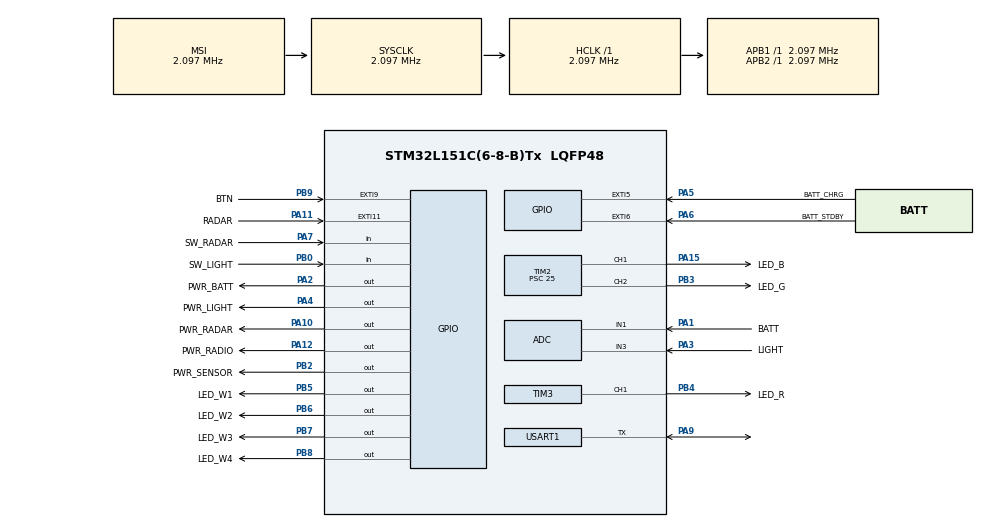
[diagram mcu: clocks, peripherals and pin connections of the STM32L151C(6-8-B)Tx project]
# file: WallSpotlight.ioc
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Mcu.Family=STM32L1
Dma.ADC.0.Mode=DMA_CIRCULAR
USART1.BaudRate=57600
NVIC.RTC_WKUP_IRQn=true\:0\:0\:false\:false\:true\:true\:true
ADC.SamplingTime-19\#ChannelRegularConversion=ADC_SAMPLETIME_96CYCLES
Dma.ADC.0.Priority=DMA_PRIORITY_LOW
VP_RTC_VS_RTC_Activate.Mode=RTC_Enabled
ADC.ScanConvMode=ADC_SCAN_ENABLE
PB6.GPIO_Label=LED_W2
PA6.GPIO_Label=BATT_STDBY
PB0.GPIO_Label=SW_LIGHT
PA11.GPIO_PuPd=GPIO_PULLDOWN
TIM2.Channel-PWM\ Generation2\ CH2=TIM_CHANNEL_2
ProjectManager.StackSize=0x400
ADC.Channel-19\#ChannelRegularConversion=ADC_CHANNEL_VREFINT
RTC.WakeUpClock-WakeUp=RTC_WAKEUPCLOCK_CK_SPRE_16BITS
ADC.NbrOfConversion=3
PA15.GPIO_Label=LED_B
PA12.Signal=GPIO_Output
PA10.PinState=GPIO_PIN_SET
Dma.ADC.0.PeriphInc=DMA_PINC_DISABLE
RCC.HCLKFreq_Value=2097000
RCC.APB2TimFreq_Value=2097000
TIM3.Period=255
PB6.Signal=GPIO_Output
PB9.GPIO_ModeDefaultEXTI=GPIO_MODE_IT_FALLING
RCC.AHBFreq_Value=2097000
Dma.ADC.0.Direction=DMA_PERIPH_TO_MEMORY
TIM3.Channel-PWM\ Generation1\ CH1=TIM_CHANNEL_1
ADC.Channel-17\#ChannelRegularConversion=ADC_CHANNEL_1
NVIC.EXTI15_10_IRQn=true\:0\:0\:false\:false\:true\:true\:true
PA12.PinState=GPIO_PIN_SET
RCC.HSE_VALUE=24000000
PB2.Signal=GPIO_Output
RCC.RTCClockSelection=RCC_RTCCLKSOURCE_LSE
PA2.PinState=GPIO_PIN_SET
PA6.GPIO_PuPd=GPIO_PULLUP
PC14-OSC32_IN.Mode=LSE-External-Oscillator
RCC.RTCClockSelectionVirtual=RCC_RTCCLKSOURCE_LSE
PA14.Mode=Serial_Wire
TIM3.Prescaler=25
PA5.GPIO_PuPd=GPIO_PULLUP
PA10.GPIO_Label=PWR_RADAR
PB7.Signal=GPIO_Output
TIM2.Channel-PWM\ Generation1\ CH1=TIM_CHANNEL_1
SH.S_TIM3_CH1.0=TIM3_CH1,PWM Generation1 CH1
Dma.ADC.0.MemInc=DMA_MINC_ENABLE
PB7.GPIO_Label=LED_W3
Mcu.Package=LQFP48
PB9.Signal=GPXTI9
TIM2.Prescaler=25
PA6.Signal=GPXTI6
PA2.GPIO_ModeDefaultOutputPP=GPIO_MODE_OUTPUT_OD
PA2.GPIO_Label=PWR_BATT
Dma.ADC.0.Instance=DMA1_Channel1
RTC.WakeUpCounter-WakeUp=1111
PA10.Signal=GPIO_Output
PB9.GPIO_PuPd=GPIO_PULLUP
VP_RTC_VS_RTC_Calendar.Mode=RTC_Calendar
ADC.Rank-19\#ChannelRegularConversion=3
PA15.Signal=S_TIM2_CH1_ETR
Dma.ADC.0.MemDataAlignment=DMA_MDATAALIGN_WORD
PB5.GPIO_Label=LED_W1
RCC.APB1TimFreq_Value=2097000
ADC.SamplingTime-18\#ChannelRegularConversion=ADC_SAMPLETIME_96CYCLES
Dma.Request0=ADC
PA4.GPIO_Label=PWR_LIGHT
PB4.Signal=S_TIM3_CH1
PA3.Signal=ADC_IN3
PB3.GPIO_Label=LED_G
ADC.Rank-17\#ChannelRegularConversion=1
RCC.MSI_VALUE=2097000
PC15-OSC32_OUT.Mode=LSE-External-Oscillator
ADC.Channel-18\#ChannelRegularConversion=ADC_CHANNEL_3
PA5.GPIO_ModeDefaultEXTI=GPIO_MODE_IT_RISING_FALLING
PA6.GPIO_ModeDefaultEXTI=GPIO_MODE_IT_RISING_FALLING
PB9.GPIO_Label=BTN
VP_ADC_Vref_Input.Mode=IN-Vrefint
PA11.GPIO_Label=RADAR
PC14-OSC32_IN.Signal=RCC_OSC32_IN
PA12.GPIO_Label=PWR_RADIO
Dma.ADC.0.PeriphDataAlignment=DMA_PDATAALIGN_WORD
PA3.Mode=IN3
PA13.Signal=SYS_JTMS-SWDIO
PB8.GPIO_Label=LED_W4
SH.S_TIM2_CH2.0=TIM2_CH2,PWM Generation2 CH2
PA9.Mode=Half_duplex(single_wire_mode)
ProjectManager.TargetToolchain=Makefile
PA9.Signal=USART1_TX
ADC.NbrOfConversionFlag=1
PC15-OSC32_OUT.Signal=RCC_OSC32_OUT
PA1.Signal=ADC_IN1
PA5.Signal=GPXTI5
board=custom
RCC.VCOOutputFreq_Value=48000000
ADC.Rank-18\#ChannelRegularConversion=2
RCC.APB2Freq_Value=2097000
PA1.Mode=IN1
PB4.GPIO_Label=LED_R
VP_TIM2_VS_ClockSourceINT.Mode=Internal
PA1.GPIO_Label=BATT
TIM2.Period=255
PA13.Mode=Serial_Wire
PB2.PinState=GPIO_PIN_SET
Mcu.Name=STM32L151C(6-8-B)Tx
PA2.Signal=GPIO_Output
PB3.Signal=S_TIM2_CH2
PA4.Signal=GPIO_Output
RCC.SYSCLKFreq_VALUE=2097000
PB5.Signal=GPIO_Output
PA7.GPIO_Label=SW_RADAR
PA5.GPIO_Label=BATT_CHRG
USART1.VirtualMode=VM_ASYNC
PA11.Signal=GPXTI11
SH.S_TIM2_CH1_ETR.0=TIM2_CH1,PWM Generation1 CH1
NVIC.EXTI9_5_IRQn=true\:0\:0\:false\:false\:true\:true\:true
PA14.Signal=SYS_JTCK-SWCLK
PB2.GPIO_Label=PWR_SENSOR
ProjectManager.HeapSize=0x200
RCC.HSI_VALUE=16000000
VP_RTC_VS_RTC_WakeUp_intern.Mode=WakeUp
NVIC.PriorityGroup=NVIC_PRIORITYGROUP_4
PB8.Signal=GPIO_Output
NVIC.DMA1_Channel1_IRQn=true\:0\:0\:false\:false\:true\:false\:true
ADC.SamplingTime-17\#ChannelRegularConversion=ADC_SAMPLETIME_96CYCLES
PA11.GPIO_ModeDefaultEXTI=GPIO_MODE_IT_RISING
RCC.APB1Freq_Value=2097000
PB0.Signal=GPIO_Input
ADC.ContinuousConvMode=ENABLE
PA3.GPIO_Label=LIGHT
PA7.Signal=GPIO_Input

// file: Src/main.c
/* USER CODE BEGIN Header */
/**
  ******************************************************************************
  * @file           : main.c
  * @brief          : Main program body
  ******************************************************************************
  * @attention
  *
  * <h2><center>&copy; Copyright (c) 2020 STMicroelectronics.
  * All rights reserved.</center></h2>
  *
  * This software component is licensed by ST under BSD 3-Clause license,
  * the "License"; You may not use this file except in compliance with the
  * License. You may obtain a copy of the License at:
  *                        opensource.org/licenses/BSD-3-Clause
  *
  ******************************************************************************
  */
/* USER CODE END Header */

#include "main.h"

ADC_HandleTypeDef hadc;
DMA_HandleTypeDef hdma_adc;

RTC_HandleTypeDef hrtc;

TIM_HandleTypeDef htim2;
TIM_HandleTypeDef htim3;

UART_HandleTypeDef huart1;

void SystemClock_Config(void);
static void MX_GPIO_Init(void);
static void MX_DMA_Init(void);
void MX_ADC_Init(void);
static void MX_USART1_UART_Init(void);
static void MX_RTC_Init(void);
static void MX_TIM2_Init(void);
static void MX_TIM3_Init(void);
/* USER CODE BEGIN PFP */
extern void wallspotlight_app();
/* USER CODE END PFP */

int main(void)
{

  /* MCU Configuration--------------------------------------------------------*/

  /* Reset of all peripherals, Initializes the Flash interface and the Systick. */
  HAL_Init();

  /* Configure the system clock */
  SystemClock_Config();

  /* Initialize all configured peripherals */
  MX_GPIO_Init();
  MX_DMA_Init();
  MX_ADC_Init();
  MX_USART1_UART_Init();
  MX_RTC_Init();
  MX_TIM2_Init();
  MX_TIM3_Init();

  /* Infinite loop */
  while (1)
  {

    /* USER CODE BEGIN 3 */
    wallspotlight_app();
  }
  /* USER CODE END 3 */
}

void SystemClock_Config(void)
{
  RCC_OscInitTypeDef RCC_OscInitStruct = {0};
  RCC_ClkInitTypeDef RCC_ClkInitStruct = {0};
  RCC_PeriphCLKInitTypeDef PeriphClkInit = {0};

  /** Configure the main internal regulator output voltage
  */
  __HAL_PWR_VOLTAGESCALING_CONFIG(PWR_REGULATOR_VOLTAGE_SCALE1);
  /** Initializes the CPU, AHB and APB busses clocks
  */
  RCC_OscInitStruct.OscillatorType = RCC_OSCILLATORTYPE_HSI|RCC_OSCILLATORTYPE_LSE
                              |RCC_OSCILLATORTYPE_MSI;
  RCC_OscInitStruct.LSEState = RCC_LSE_ON;
  RCC_OscInitStruct.HSIState = RCC_HSI_ON;
  RCC_OscInitStruct.HSICalibrationValue = RCC_HSICALIBRATION_DEFAULT;
  RCC_OscInitStruct.MSIState = RCC_MSI_ON;
  RCC_OscInitStruct.MSICalibrationValue = 0;
  RCC_OscInitStruct.MSIClockRange = RCC_MSIRANGE_5;
  RCC_OscInitStruct.PLL.PLLState = RCC_PLL_NONE;
  if (HAL_RCC_OscConfig(&RCC_OscInitStruct) != HAL_OK)
  {
    Error_Handler();
  }
  /** Initializes the CPU, AHB and APB busses clocks
  */
  RCC_ClkInitStruct.ClockType = RCC_CLOCKTYPE_HCLK|RCC_CLOCKTYPE_SYSCLK
                              |RCC_CLOCKTYPE_PCLK1|RCC_CLOCKTYPE_PCLK2;
  RCC_ClkInitStruct.SYSCLKSource = RCC_SYSCLKSOURCE_MSI;
  RCC_ClkInitStruct.AHBCLKDivider = RCC_SYSCLK_DIV1;
  RCC_ClkInitStruct.APB1CLKDivider = RCC_HCLK_DIV1;
  RCC_ClkInitStruct.APB2CLKDivider = RCC_HCLK_DIV1;

  if (HAL_RCC_ClockConfig(&RCC_ClkInitStruct, FLASH_LATENCY_0) != HAL_OK)
  {
    Error_Handler();
  }
  PeriphClkInit.PeriphClockSelection = RCC_PERIPHCLK_RTC;
  PeriphClkInit.RTCClockSelection = RCC_RTCCLKSOURCE_LSE;
  if (HAL_RCCEx_PeriphCLKConfig(&PeriphClkInit) != HAL_OK)
  {
    Error_Handler();
  }
}

void MX_ADC_Init(void)
{

  ADC_ChannelConfTypeDef sConfig = {0};

  /** Configure the global features of the ADC (Clock, Resolution, Data Alignment and number of conversion)
  */
  hadc.Instance = ADC1;
  hadc.Init.ClockPrescaler = ADC_CLOCK_ASYNC_DIV1;
  hadc.Init.Resolution = ADC_RESOLUTION_12B;
  hadc.Init.DataAlign = ADC_DATAALIGN_RIGHT;
  hadc.Init.ScanConvMode = ADC_SCAN_ENABLE;
  hadc.Init.EOCSelection = ADC_EOC_SEQ_CONV;
  hadc.Init.LowPowerAutoWait = ADC_AUTOWAIT_DISABLE;
  hadc.Init.LowPowerAutoPowerOff = ADC_AUTOPOWEROFF_DISABLE;
  hadc.Init.ChannelsBank = ADC_CHANNELS_BANK_A;
  hadc.Init.ContinuousConvMode = ENABLE;
  hadc.Init.NbrOfConversion = 3;
  hadc.Init.DiscontinuousConvMode = DISABLE;
  hadc.Init.ExternalTrigConv = ADC_SOFTWARE_START;
  hadc.Init.ExternalTrigConvEdge = ADC_EXTERNALTRIGCONVEDGE_NONE;
  hadc.Init.DMAContinuousRequests = DISABLE;
  if (HAL_ADC_Init(&hadc) != HAL_OK)
  {
    Error_Handler();
  }
  /** Configure for the selected ADC regular channel its corresponding rank in the sequencer and its sample time.
  */
  sConfig.Channel = ADC_CHANNEL_1;
  sConfig.Rank = ADC_REGULAR_RANK_1;
  sConfig.SamplingTime = ADC_SAMPLETIME_96CYCLES;
  if (HAL_ADC_ConfigChannel(&hadc, &sConfig) != HAL_OK)
  {
    Error_Handler();
  }
  /** Configure for the selected ADC regular channel its corresponding rank in the sequencer and its sample time.
  */
  sConfig.Channel = ADC_CHANNEL_3;
  sConfig.Rank = ADC_REGULAR_RANK_2;
  if (HAL_ADC_ConfigChannel(&hadc, &sConfig) != HAL_OK)
  {
    Error_Handler();
  }
  /** Configure for the selected ADC regular channel its corresponding rank in the sequencer and its sample time.
  */
  sConfig.Channel = ADC_CHANNEL_VREFINT;
  sConfig.Rank = ADC_REGULAR_RANK_3;
  if (HAL_ADC_ConfigChannel(&hadc, &sConfig) != HAL_OK)
  {
    Error_Handler();
  }

}

static void MX_RTC_Init(void)
{

  RTC_TimeTypeDef sTime = {0};
  RTC_DateTypeDef sDate = {0};

  /** Initialize RTC Only
  */
  hrtc.Instance = RTC;
  hrtc.Init.HourFormat = RTC_HOURFORMAT_24;
  hrtc.Init.AsynchPrediv = 127;
  hrtc.Init.SynchPrediv = 255;
  hrtc.Init.OutPut = RTC_OUTPUT_DISABLE;
  hrtc.Init.OutPutPolarity = RTC_OUTPUT_POLARITY_HIGH;
  hrtc.Init.OutPutType = RTC_OUTPUT_TYPE_OPENDRAIN;
  if (HAL_RTC_Init(&hrtc) != HAL_OK)
  {
    Error_Handler();
  }

  /** Initialize RTC and set the Time and Date
  */
  sTime.Hours = 0x0;
  sTime.Minutes = 0x0;
  sTime.Seconds = 0x0;
  sTime.DayLightSaving = RTC_DAYLIGHTSAVING_NONE;
  sTime.StoreOperation = RTC_STOREOPERATION_RESET;
  if (HAL_RTC_SetTime(&hrtc, &sTime, RTC_FORMAT_BCD) != HAL_OK)
  {
    Error_Handler();
  }
  sDate.WeekDay = RTC_WEEKDAY_MONDAY;
  sDate.Month = RTC_MONTH_JANUARY;
  sDate.Date = 0x1;
  sDate.Year = 0x0;

  if (HAL_RTC_SetDate(&hrtc, &sDate, RTC_FORMAT_BCD) != HAL_OK)
  {
    Error_Handler();
  }
  /** Enable the WakeUp
  */
  if (HAL_RTCEx_SetWakeUpTimer_IT(&hrtc, 1111, RTC_WAKEUPCLOCK_CK_SPRE_16BITS) != HAL_OK)
  {
    Error_Handler();
  }

}

static void MX_TIM2_Init(void)
{

  TIM_ClockConfigTypeDef sClockSourceConfig = {0};
  TIM_MasterConfigTypeDef sMasterConfig = {0};
  TIM_OC_InitTypeDef sConfigOC = {0};

  htim2.Instance = TIM2;
  htim2.Init.Prescaler = 25;
  htim2.Init.CounterMode = TIM_COUNTERMODE_UP;
  htim2.Init.Period = 255;
  htim2.Init.ClockDivision = TIM_CLOCKDIVISION_DIV1;
  htim2.Init.AutoReloadPreload = TIM_AUTORELOAD_PRELOAD_DISABLE;
  if (HAL_TIM_Base_Init(&htim2) != HAL_OK)
  {
    Error_Handler();
  }
  sClockSourceConfig.ClockSource = TIM_CLOCKSOURCE_INTERNAL;
  if (HAL_TIM_ConfigClockSource(&htim2, &sClockSourceConfig) != HAL_OK)
  {
    Error_Handler();
  }
  if (HAL_TIM_PWM_Init(&htim2) != HAL_OK)
  {
    Error_Handler();
  }
  sMasterConfig.MasterOutputTrigger = TIM_TRGO_RESET;
  sMasterConfig.MasterSlaveMode = TIM_MASTERSLAVEMODE_DISABLE;
  if (HAL_TIMEx_MasterConfigSynchronization(&htim2, &sMasterConfig) != HAL_OK)
  {
    Error_Handler();
  }
  sConfigOC.OCMode = TIM_OCMODE_PWM1;
  sConfigOC.Pulse = 0;
  sConfigOC.OCPolarity = TIM_OCPOLARITY_HIGH;
  sConfigOC.OCFastMode = TIM_OCFAST_DISABLE;
  if (HAL_TIM_PWM_ConfigChannel(&htim2, &sConfigOC, TIM_CHANNEL_1) != HAL_OK)
  {
    Error_Handler();
  }
  if (HAL_TIM_PWM_ConfigChannel(&htim2, &sConfigOC, TIM_CHANNEL_2) != HAL_OK)
  {
    Error_Handler();
  }
  HAL_TIM_MspPostInit(&htim2);

}

static void MX_TIM3_Init(void)
{

  TIM_MasterConfigTypeDef sMasterConfig = {0};
  TIM_OC_InitTypeDef sConfigOC = {0};

  htim3.Instance = TIM3;
  htim3.Init.Prescaler = 25;
  htim3.Init.CounterMode = TIM_COUNTERMODE_UP;
  htim3.Init.Period = 255;
  htim3.Init.ClockDivision = TIM_CLOCKDIVISION_DIV1;
  htim3.Init.AutoReloadPreload = TIM_AUTORELOAD_PRELOAD_DISABLE;
  if (HAL_TIM_PWM_Init(&htim3) != HAL_OK)
  {
    Error_Handler();
  }
  sMasterConfig.MasterOutputTrigger = TIM_TRGO_RESET;
  sMasterConfig.MasterSlaveMode = TIM_MASTERSLAVEMODE_DISABLE;
  if (HAL_TIMEx_MasterConfigSynchronization(&htim3, &sMasterConfig) != HAL_OK)
  {
    Error_Handler();
  }
  sConfigOC.OCMode = TIM_OCMODE_PWM1;
  sConfigOC.Pulse = 0;
  sConfigOC.OCPolarity = TIM_OCPOLARITY_HIGH;
  sConfigOC.OCFastMode = TIM_OCFAST_DISABLE;
  if (HAL_TIM_PWM_ConfigChannel(&htim3, &sConfigOC, TIM_CHANNEL_1) != HAL_OK)
  {
    Error_Handler();
  }
  HAL_TIM_MspPostInit(&htim3);

}

static void MX_USART1_UART_Init(void)
{

  huart1.Instance = USART1;
  huart1.Init.BaudRate = 57600;
  huart1.Init.WordLength = UART_WORDLENGTH_8B;
  huart1.Init.StopBits = UART_STOPBITS_1;
  huart1.Init.Parity = UART_PARITY_NONE;
  huart1.Init.Mode = UART_MODE_TX_RX;
  huart1.Init.HwFlowCtl = UART_HWCONTROL_NONE;
  huart1.Init.OverSampling = UART_OVERSAMPLING_16;
  if (HAL_HalfDuplex_Init(&huart1) != HAL_OK)
  {
    Error_Handler();
  }

}

static void MX_DMA_Init(void)
{

  /* DMA controller clock enable */
  __HAL_RCC_DMA1_CLK_ENABLE();

  /* DMA interrupt init */
  /* DMA1_Channel1_IRQn interrupt configuration */
  HAL_NVIC_SetPriority(DMA1_Channel1_IRQn, 0, 0);
  HAL_NVIC_EnableIRQ(DMA1_Channel1_IRQn);

}

static void MX_GPIO_Init(void)
{
  GPIO_InitTypeDef GPIO_InitStruct = {0};

  /* GPIO Ports Clock Enable */
  __HAL_RCC_GPIOC_CLK_ENABLE();
  __HAL_RCC_GPIOH_CLK_ENABLE();
  __HAL_RCC_GPIOA_CLK_ENABLE();
  __HAL_RCC_GPIOB_CLK_ENABLE();

  /*Configure GPIO pin Output Level */
  HAL_GPIO_WritePin(GPIOA, PWR_BATT_Pin|PWR_RADAR_Pin|PWR_RADIO_Pin, GPIO_PIN_SET);

  /*Configure GPIO pin Output Level */
  HAL_GPIO_WritePin(PWR_LIGHT_GPIO_Port, PWR_LIGHT_Pin, GPIO_PIN_RESET);

  /*Configure GPIO pin Output Level */
  HAL_GPIO_WritePin(PWR_SENSOR_GPIO_Port, PWR_SENSOR_Pin, GPIO_PIN_SET);

  /*Configure GPIO pin Output Level */
  HAL_GPIO_WritePin(GPIOB, LED_W1_Pin|LED_W2_Pin|LED_W3_Pin|LED_W4_Pin, GPIO_PIN_RESET);

  /*Configure GPIO pin : PC13 */
  GPIO_InitStruct.Pin = GPIO_PIN_13;
  GPIO_InitStruct.Mode = GPIO_MODE_ANALOG;
  GPIO_InitStruct.Pull = GPIO_NOPULL;
  HAL_GPIO_Init(GPIOC, &GPIO_InitStruct);

  /*Configure GPIO pins : PH0 PH1 */
  GPIO_InitStruct.Pin = GPIO_PIN_0|GPIO_PIN_1;
  GPIO_InitStruct.Mode = GPIO_MODE_ANALOG;
  GPIO_InitStruct.Pull = GPIO_NOPULL;
  HAL_GPIO_Init(GPIOH, &GPIO_InitStruct);

  /*Configure GPIO pins : PA0 PA8 */
  GPIO_InitStruct.Pin = GPIO_PIN_0|GPIO_PIN_8;
  GPIO_InitStruct.Mode = GPIO_MODE_ANALOG;
  GPIO_InitStruct.Pull = GPIO_NOPULL;
  HAL_GPIO_Init(GPIOA, &GPIO_InitStruct);

  /*Configure GPIO pin : PWR_BATT_Pin */
  GPIO_InitStruct.Pin = PWR_BATT_Pin;
  GPIO_InitStruct.Mode = GPIO_MODE_OUTPUT_OD;
  GPIO_InitStruct.Pull = GPIO_NOPULL;
  GPIO_InitStruct.Speed = GPIO_SPEED_FREQ_LOW;
  HAL_GPIO_Init(PWR_BATT_GPIO_Port, &GPIO_InitStruct);

  /*Configure GPIO pins : PWR_LIGHT_Pin PWR_RADAR_Pin PWR_RADIO_Pin */
  GPIO_InitStruct.Pin = PWR_LIGHT_Pin|PWR_RADAR_Pin|PWR_RADIO_Pin;
  GPIO_InitStruct.Mode = GPIO_MODE_OUTPUT_PP;
  GPIO_InitStruct.Pull = GPIO_NOPULL;
  GPIO_InitStruct.Speed = GPIO_SPEED_FREQ_LOW;
  HAL_GPIO_Init(GPIOA, &GPIO_InitStruct);

  /*Configure GPIO pins : BATT_CHRG_Pin BATT_STDBY_Pin */
  GPIO_InitStruct.Pin = BATT_CHRG_Pin|BATT_STDBY_Pin;
  GPIO_InitStruct.Mode = GPIO_MODE_IT_RISING_FALLING;
  GPIO_InitStruct.Pull = GPIO_PULLUP;
  HAL_GPIO_Init(GPIOA, &GPIO_InitStruct);

  /*Configure GPIO pin : SW_RADAR_Pin */
  GPIO_InitStruct.Pin = SW_RADAR_Pin;
  GPIO_InitStruct.Mode = GPIO_MODE_INPUT;
  GPIO_InitStruct.Pull = GPIO_NOPULL;
  HAL_GPIO_Init(SW_RADAR_GPIO_Port, &GPIO_InitStruct);

  /*Configure GPIO pin : SW_LIGHT_Pin */
  GPIO_InitStruct.Pin = SW_LIGHT_Pin;
  GPIO_InitStruct.Mode = GPIO_MODE_INPUT;
  GPIO_InitStruct.Pull = GPIO_NOPULL;
  HAL_GPIO_Init(SW_LIGHT_GPIO_Port, &GPIO_InitStruct);

  /*Configure GPIO pins : PB1 PB10 PB11 PB12
                           PB13 PB14 PB15 */
  GPIO_InitStruct.Pin = GPIO_PIN_1|GPIO_PIN_10|GPIO_PIN_11|GPIO_PIN_12
                          |GPIO_PIN_13|GPIO_PIN_14|GPIO_PIN_15;
  GPIO_InitStruct.Mode = GPIO_MODE_ANALOG;
  GPIO_InitStruct.Pull = GPIO_NOPULL;
  HAL_GPIO_Init(GPIOB, &GPIO_InitStruct);

  /*Configure GPIO pins : PWR_SENSOR_Pin LED_W1_Pin LED_W2_Pin LED_W3_Pin
                           LED_W4_Pin */
  GPIO_InitStruct.Pin = PWR_SENSOR_Pin|LED_W1_Pin|LED_W2_Pin|LED_W3_Pin
                          |LED_W4_Pin;
  GPIO_InitStruct.Mode = GPIO_MODE_OUTPUT_PP;
  GPIO_InitStruct.Pull = GPIO_NOPULL;
  GPIO_InitStruct.Speed = GPIO_SPEED_FREQ_LOW;
  HAL_GPIO_Init(GPIOB, &GPIO_InitStruct);

  /*Configure GPIO pin : RADAR_Pin */
  GPIO_InitStruct.Pin = RADAR_Pin;
  GPIO_InitStruct.Mode = GPIO_MODE_IT_RISING;
  GPIO_InitStruct.Pull = GPIO_PULLDOWN;
  HAL_GPIO_Init(RADAR_GPIO_Port, &GPIO_InitStruct);

  /*Configure GPIO pin : BTN_Pin */
  GPIO_InitStruct.Pin = BTN_Pin;
  GPIO_InitStruct.Mode = GPIO_MODE_IT_FALLING;
  GPIO_InitStruct.Pull = GPIO_PULLUP;
  HAL_GPIO_Init(BTN_GPIO_Port, &GPIO_InitStruct);

  /* EXTI interrupt init*/
  HAL_NVIC_SetPriority(EXTI9_5_IRQn, 0, 0);
  HAL_NVIC_EnableIRQ(EXTI9_5_IRQn);

  HAL_NVIC_SetPriority(EXTI15_10_IRQn, 0, 0);
  HAL_NVIC_EnableIRQ(EXTI15_10_IRQn);

}

void Error_Handler(void)
{
}

/************************ (C) COPYRIGHT STMicroelectronics *****END OF FILE****/
